# R7FA6M5BH register map
Vendor: Renesas Electronics Corporation; Series: RA6; File version: 1.20.01
CPU: CM33 r0p4, little endian, MPU, FPU, VTOR, 4 interrupt priority bits, 96 interrupts
Registers are 32-bit, read-write, reset 0x0 unless marked. A register's access mark holds for its fields unless they carry their own. Offsets are from the block's base; [hi:lo] are bit positions.

## TSN — Temperature Sensor
Base 0x400F3000
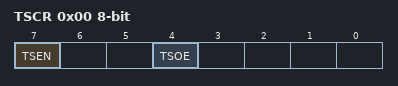
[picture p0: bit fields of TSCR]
0x00 TSCR 8-bit — Temperature Sensor Control Register
  [7] TSEN — Temperature Sensor Enable
    0=Stop the temperature sensor; 1=Start the temperature sensor
  [4] TSOE — Temperature Sensor Output Enable
    0=Disable output from the temperature sensor to the ADC12; 1=Enable output from the temperature sensor to the ADC12

## CRC — Cyclic Redundancy Check Calculator
Base 0x40108000
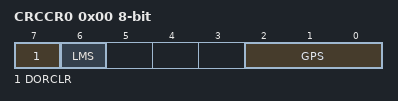
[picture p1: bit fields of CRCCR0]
0x00 CRCCR0 8-bit — CRC Control Register 0
  [7] DORCLR wo — CRCDOR/CRCDOR_HA/CRCDOR_BY Register Clear
    0=No effect; 1=Clear the CRCDOR/CRCDOR_HA/CRCDOR_BY register
  [6] LMS — CRC Calculation Switching
    0=Generate CRC code for LSB-first communication; 1=Generate CRC code for MSB-first communication
  [2:0] GPS — CRC Generating Polynomial Switching
    1=8-bit CRC-8 (X8 + X2 + X + 1); 2=16-bit CRC-16 (X16 + X15 + X2 + 1); 3=16-bit CRC-CCITT (X16 + X12 + X5 + 1); 4=32-bit CRC-32 (X32 + X26 + X23 + X22 + X16 + X12 + X11 +X10 + X8 + X7 + X5 + X4 + X2 + X + 1); 5=32-bit CRC-32C (X32 + X28 + X27 + X26 + X25 + X23 + X22 + X20 + X19 + X18 + X14 + X13 + X11 + X10 + X9 + X8 + X6 + 1); other=Others (No calculation is executed)
0x04 CRCDIR — CRC Data Input Register
0x04 CRCDIR_BY 8-bit (alternate view of CRCDIR) — CRC Data Input Register
0x08 CRCDOR — CRC Data Output Register
0x08 CRCDOR_HA 16-bit (alternate view of CRCDOR) — CRC Data Output Register
0x08 CRCDOR_BY 8-bit (alternate view of CRCDOR) — CRC Data Output Register

## DOC — Data Operation Circuit
Base 0x40109000
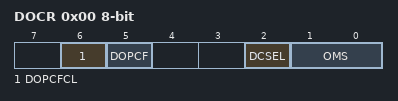
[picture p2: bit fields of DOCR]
0x00 DOCR 8-bit — DOC Control Register
  [6] DOPCFCL — DOPCF Clear
    0=Retain DOPCF flag state; 1=Clear DOPCF flag
  [5] DOPCF ro — DOC Flag
  [2] DCSEL — Detection Condition Select
    0=Set DOPCF flag when data mismatch is detected; 1=Set DOPCF flag when data match is detected
  [1:0] OMS — Operating Mode Select
    0=Data comparison mode; 1=Data addition mode; 2=Data subtraction mode; 3=Setting prohibited
0x02 DODIR 16-bit — DOC Data Input Register
0x04 DODSR 16-bit — DOC Data Setting Register

## ECCAFL0 — ECCAFL
Base 0x4012F000
Same registers: ECCAFL1 0x4012F100, ECCMB 0x4012F200
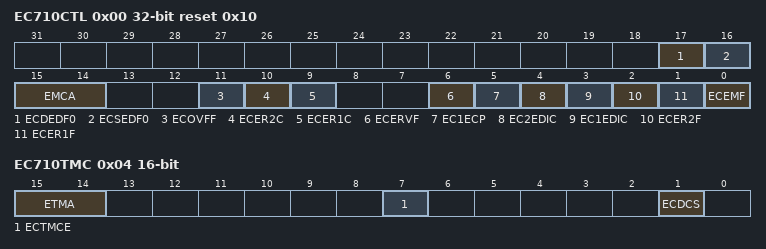
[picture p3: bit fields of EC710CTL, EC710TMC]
0x00 EC710CTL reset 0x10 — ECC Control Register
  [17] ECDEDF0 ro — ECC Dual Bit Error Address Detection Flag
    0=There is no bit error in EC710EAD0 after reset or clearing ECER2F bit; 1=Address captured in EC710EAD0 shows that 2-bit error occurred and captured
  [16] ECSEDF0 ro — ECC Single bit Error Address Detection Flag
    0=There is no bit error in EC710EAD0 after reset or clearing ECER1F bit; 1=Address captured in EC710EAD0 shows that 1-bit error occurred and captured
  [15:14] EMCA — Access Control to ECC Mode Select bit
  [11] ECOVFF ro — ECC Overflow Detection Flag
    0=No effect; 1=ECC overflow detection flag
  [10] ECER2C — 2-bit ECC Error Detection Flag Clear
    0=No effect; 1=Clear 2-bit ECC error detection flag
  [9] ECER1C — Accumulating ECC Error Detection and Correction Flag Clear
    0=No effect; 1=Clear accumulating ECC error detection and correction flag
  [6] ECERVF — ECC Error Judgment Enable Flag
    0=Error judgment disable; 1=Error judgment enable
  [5] EC1ECP — ECC 1-bit Error Correction Permission
    0=At 1-bit error detection, the error correction is executed; 1=At 1-bit error detection, the error correction is not executed
  [4] EC2EDIC — ECC 2-bit Error Detection Interrupt Control
    0=Disable 2-bit error detection interrupt request; 1=Enable 2-bit error detection interrupt request
  [3] EC1EDIC — ECC 1-bit Error Detection Interrupt Control
    0=Disable 1-bit error detection interrupt request; 1=Enable 1-bit error detection interrupt request
  [2] ECER2F ro — 2-bit ECC Error Detection Flag
    0=After clearing this bit, 2-bit error has not occurred; 1=2-bit error has occurred
  [1] ECER1F ro — ECC Error Detection and Correction Flag
    0=After clearing this bit, 1-bit error correction has not occurred; 1=1-bit error has occurred
  [0] ECEMF ro — ECC Error Message Flag
    0=There is no bit error in present RAM output data; 1=There is bit error in present RAM output data
0x04 EC710TMC 16-bit — ECC Test Mode Control Register
  [15:14] ETMA — ECC Test Mode Bit Access Control
  [7] ECTMCE — ECC Test Mode Control Enable
    0=The access to test mode register and bit is disabled; 1=The access to test mode register and bit is enabled
  [1] ECDCS — ECC Decode Input Select
    0=Input lower 32 bits of RAM output data to data area of decode circuit; 1=Input ECEDB31-0 in EC710TED register to data area of decode circuit
0x0C EC710TED — ECC Test Substitute Data Register
  [31:0] ECEDB — ECC Test Substitute Data
0x10 EC710EAD0 ro — ECC Error Address Register
  [10:0] ECEAD — ECC Error Address
